# GD32G5x3 register map
File version: 1.0
CPU: CM33 r2p1, little endian, MPU, FPU, 4 interrupt priority bits
Registers are 32-bit, read-write, reset 0x0 unless marked. A register's access mark holds for its fields unless they carry their own. Offsets are from the block's base; [hi:lo] are bit positions; {n}, {i} and the like mark numbered series.

## TIMER15 — General level4 timer
Base 0x40014400
Same registers: TIMER16 0x40014800
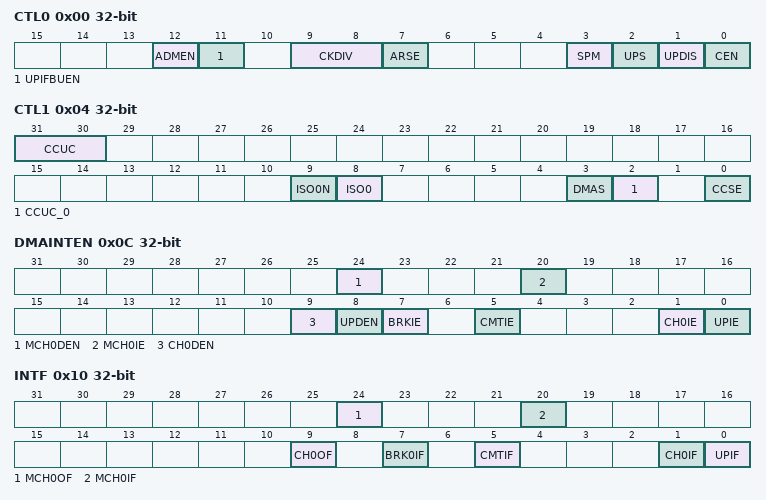
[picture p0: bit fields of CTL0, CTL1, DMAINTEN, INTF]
0x00 CTL0 — Control register 0
  [12] ADMEN — Adjustment mode enable
  [11] UPIFBUEN — UPIF bit backup enable
  [9:8] CKDIV — Clock division
  [7] ARSE — Auto-reload shadow enable
  [3] SPM — Single pulse mode
  [2] UPS — Update source
  [1] UPDIS — Update disable
  [0] CEN — Counter enable
0x04 CTL1 — Control register 1
  [31:30] CCUC — Commutation control shadow register update control
  [9] ISO0N — Idle state of multi mode channel 0 complementary output
  [8] ISO0 — Idle state of channel 0 output
  [3] DMAS — DMA request source selection
  [2] CCUC_0 — Commutation control shadow register update control
  [0] CCSE — Commutation control shadow enable
0x0C DMAINTEN — DMA and interrupt enable register
  [24] MCH0DEN — Multi mode channel 0 capture/compare DMA request enable
  [20] MCH0IE — Multi mode channel 0 capture/compare interrupt enable
  [9] CH0DEN — Channel 0 capture/compare DMA request enable
  [8] UPDEN — Update DMA request enable
  [7] BRKIE — Break interrupt enable
  [5] CMTIE — Commutation interrupt enable
  [1] CH0IE — Channel 0 capture/compare interrupt enable
  [0] UPIE — Update interrupt enable
0x10 INTF — Interrupt flag register
  [24] MCH0OF — Multi mode channel 0 over capture flag
  [20] MCH0IF — Multi mode channel 0 capture/compare interrupt flag
  [9] CH0OF — Channel 0 over capture flag
  [7] BRK0IF — BREAK0 interrupt flag
  [5] CMTIF — Channel commutation interrupt flag
  [1] CH0IF — Channel 0 capture/compare interrupt flag
  [0] UPIF — Update interrupt flag
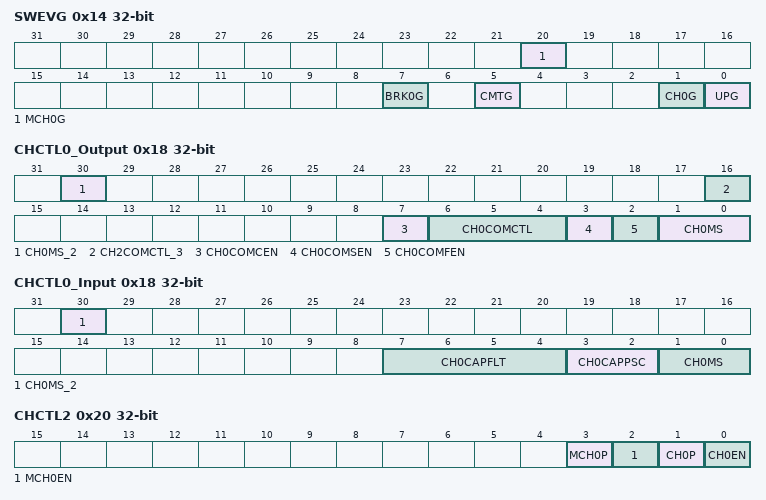
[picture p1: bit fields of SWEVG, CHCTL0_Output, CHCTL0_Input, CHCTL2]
0x14 SWEVG wo — Software event generation register
  [20] MCH0G — Multi mode channel 0 capture or compare event generation
  [7] BRK0G — BREAK0 event generation
  [5] CMTG — Channel commutation event generation
  [1] CH0G — Channel 0 capture or compare event generation
  [0] UPG — Update event generation
0x18 CHCTL0_Output — Channel control register 0 (output mode)
  [30] CH0MS_2 — bit2 of Channel 0 I/O mode selection
  [16] CH2COMCTL_3 — Bit 3 of channel 1 compare output control
  [7] CH0COMCEN — Channel 0 output compare clear enable
  [6:4] CH0COMCTL — Channel 0 compare output control
  [3] CH0COMSEN — Channel 0 compare output shadow enable
  [2] CH0COMFEN — Channel 0 output compare fast enable
  [1:0] CH0MS — Channel 0 I/O mode selection
0x18 CHCTL0_Input (alternate view of CHCTL0_Output) — Channel control register 0 (input mode)
  [30] CH0MS_2 — bit 2 of Channel 0 I/O mode selection
  [7:4] CH0CAPFLT — Channel 0 input capture filter control
  [3:2] CH0CAPPSC — Channel 0 input capture prescaler
  [1:0] CH0MS — Channel 0 mode selection
0x20 CHCTL2 — Channel control register 2
  [3] MCH0P — Multi mode channel 0 output polarity
  [2] MCH0EN — Multi mode channel 0 capture/compare enable
  [1] CH0P — Channel 0 capture/compare polarity
  [0] CH0EN — Channel 0 capture/compare enable
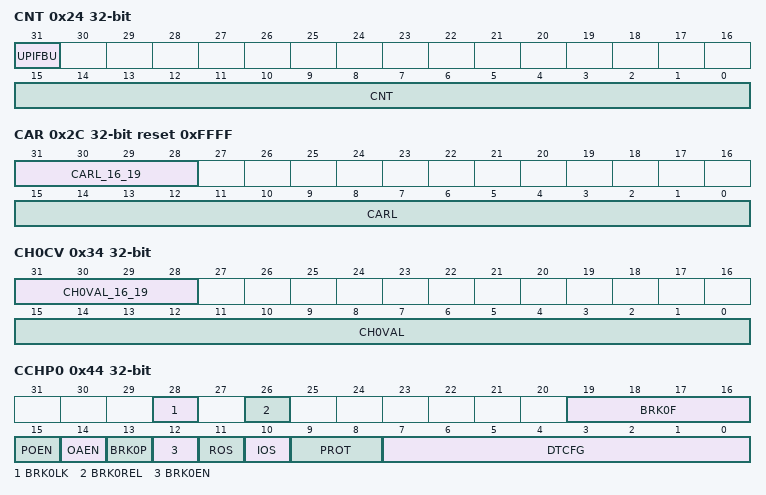
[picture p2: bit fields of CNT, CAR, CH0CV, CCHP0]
0x24 CNT access per field — >Counter register
  [31] UPIFBU ro — UPIF bit backup
  [15:0] CNT rw — This bit-field indicates the current counter value
0x28 PSC — Prescaler register
  [15:0] PSC — Prescaler value of the counter clock
0x2C CAR reset 0xFFFF — Counter auto reload register
  [31:28] CARL_16_19 — Counter auto reload value(bit 16 to 19)
  [15:0] CARL — Counter auto reload value (bit 0 to 15)
0x30 CREP0 — Counter repetition register 0
  [7:0] CREP0 — Counter repetition value 0
0x34 CH0CV — Channel 0 capture/compare value register
  [31:28] CH0VAL_16_19 — Capture / compare value of channel0(bit 16 to 19)
  [15:0] CH0VAL — Capture/compare value of channel 0 (bit 0 to 15)
0x44 CCHP0 access not given — Complementary channel protection register 0
  [28] BRK0LK rw — BREAK0 input locked
  [26] BRK0REL rw — BREAK0 input released
  [19:16] BRK0F rw — BREAK0 input signal filter
  [15] POEN rw — Primary output enable
  [14] OAEN rw — Output automatic enable
  [13] BRK0P rw — BREAK0 input signal polarity
  [12] BRK0EN rw — BREAK0 input signal enable
  [11] ROS rw — Run mode off-state enable
  [10] IOS rw — Idle mode off-state enable
  [9:8] PROT rw — Complementary register protect control
  [7:0] DTCFG — Dead time configuration
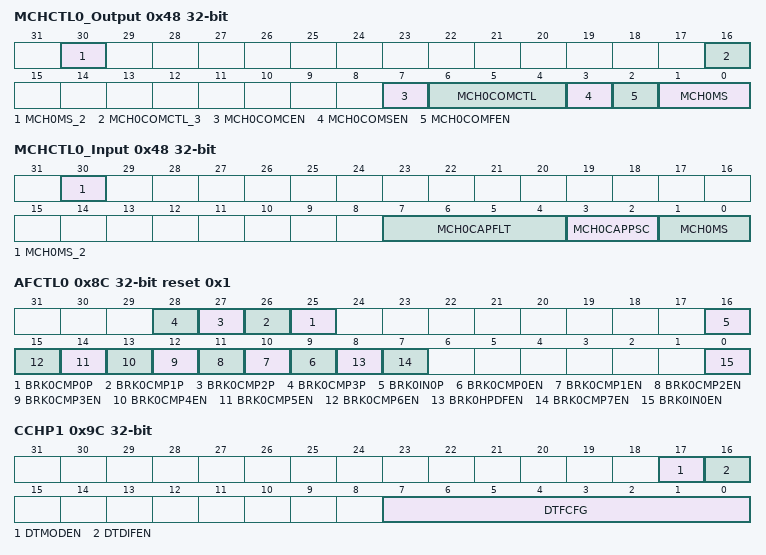
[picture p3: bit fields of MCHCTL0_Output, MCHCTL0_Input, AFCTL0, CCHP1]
0x48 MCHCTL0_Output — Multi mode channel control register 0 (output mode)
  [30] MCH0MS_2 — Multi mode channel 0 I/O mode selection
  [16] MCH0COMCTL_3 — Multi mode channel 0 compare output control.
  [7] MCH0COMCEN — Multi mode channel 0 output compare clear enable
  [6:4] MCH0COMCTL — Multi mode channel 0 output compare control
  [3] MCH0COMSEN — Multi mode channel 0 output compare shadow enable
  [2] MCH0COMFEN — Multi mode channel 0 output compare fast enable
  [1:0] MCH0MS — Multi mode channel 0 I/O mode selection
0x48 MCHCTL0_Input (alternate view of MCHCTL0_Output) — Multi mode channel control register 0 (input mode)
  [30] MCH0MS_2 — Multi mode channel 0 I/O mode selection(bit2)
  [7:4] MCH0CAPFLT — Multi mode channel 0 input capture filter control
  [3:2] MCH0CAPPSC — Multi mode channel 0 input capture prescaler
  [1:0] MCH0MS — Multi mode channel 0 I/O mode selection
0x50 MCHCTL2 — Multi mode channel control register 2
  [1:0] MCH0FP — Multi mode channel 0 capture/compare free polarity
0x54 MCH0CV — Multi mode channel 0 capture/compare value register
  [15:0] MCH0VAL — Capture/compare value of multi mode channel 0
0x74 CTL2 reset 0x300000 — Control register 2
  [21:20] MCH0MSEL — Multi mode channel 0 mode select
0x8C AFCTL0 reset 0x1 — alternate function control register 0
  [n+25] BRK0CMP{n}P (n=0..3) — BREAK0 CMP{n} input polarity
  [16] BRK0IN0P — BREAK0 BRKIN0 alternate function input polarity
  [n+9] BRK0CMP{n}EN (n=0..6) — BREAK0 CMP{n} enable
  [8] BRK0HPDFEN — BREAK0 HPDF input
  [7] BRK0CMP7EN — BREAK0 CMP7 enable
  [0] BRK0IN0EN — BREAK0 BRKIN0 alternate function input enable
0x90 AFCTL1 — alternate function control register 1
  [21:19] OCRINSEL — OCPRE_CLR inputs selection
0x98 CREP1 — Counter repetition register 1
  [31:0] CREP1 — Counter repetition value 1
0x9C CCHP1 — Complementary channel protection register 1
  [17] DTMODEN — Dead time modified on-the-fly enable
  [16] DTDIFEN — Dead time configure different enable
  [7:0] DTFCFG — Dead time falling edge configure
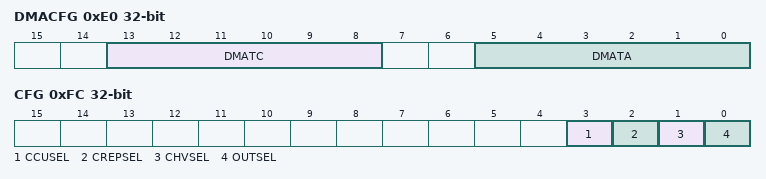
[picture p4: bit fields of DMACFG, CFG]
0xE0 DMACFG — DMA configuration register
  [13:8] DMATC — DMA transfer count
  [5:0] DMATA — DMA transfer access start address
0xE4 DMATB — DMA transfer buffer register
  [31:0] DMATB — DMA transfer buffer
0xFC CFG — Configuration register
  [3] CCUSEL — Commutation control shadow register update select
  [2] CREPSEL — The counter repetition register select
  [1] CHVSEL — Write CHxVAL register selection bit
  [0] OUTSEL — The output value selection bit
